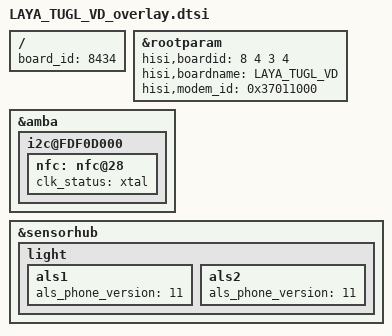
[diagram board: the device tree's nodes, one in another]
/**
 * Copyright (C) 2014 Hisilicon Ltd.
 *
 *  This program is free software; you can redistribute it and/or modify
 *  it under the terms of the GNU General Public License version 2 as
 *  publishhed by the Free Software Foundation.
 */

/include/ "LAYA_TUGL_VB_overlay.dtsi"

/ {
    board_id = <8434>;
};

    &rootparam{
        hisi,boardid = <8 4 3 4>;
        hisi,boardname = "LAYA_TUGL_VD";
        hisi,modem_id = <0x37011000>;
    };
    
    &amba {
            i2c@FDF0D000 {
                    nfc:nfc@28{
                            clk_status = "xtal";
                    };
            };
    };
    &sensorhub{
                light{
                        als1{
                               als_phone_version = <11>;
                        };
                        als2{
                               als_phone_version = <11>;
                        };
                };
    };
